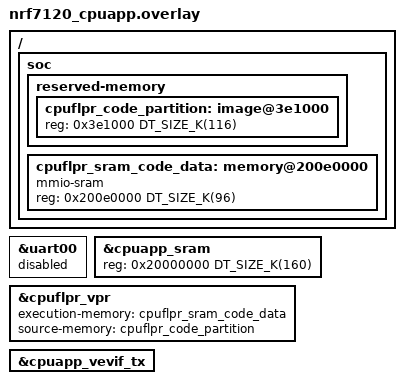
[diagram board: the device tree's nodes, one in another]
/*
 * Copyright (c) 2025 Nordic Semiconductor
 * SPDX-License-Identifier: Apache-2.0
 */

/ {
	soc {
		reserved-memory {
			#address-cells = <1>;
			#size-cells = <1>;
			cpuflpr_code_partition: image@3e1000 {
				/* FLPR core code partition */
				reg = <0x3e1000 DT_SIZE_K(116)>;
			};
		};

		cpuflpr_sram_code_data: memory@200e0000 {
			compatible = "mmio-sram";
			reg = <0x200e0000 DT_SIZE_K(96)>;
			#address-cells = <1>;
			#size-cells = <1>;
			ranges = <0x0 0x200e0000 DT_SIZE_K(96)>;
		};
	};
};

&uart00 {
	status = "reserved";
};

&cpuapp_sram {
	reg = <0x20000000 DT_SIZE_K(160)>;
	ranges = <0x0 0x20000000 0x28000>;
};

&cpuflpr_vpr {
	execution-memory = <&cpuflpr_sram_code_data>;
	source-memory = <&cpuflpr_code_partition>;
};

&cpuapp_vevif_tx {
	status = "okay";
};
